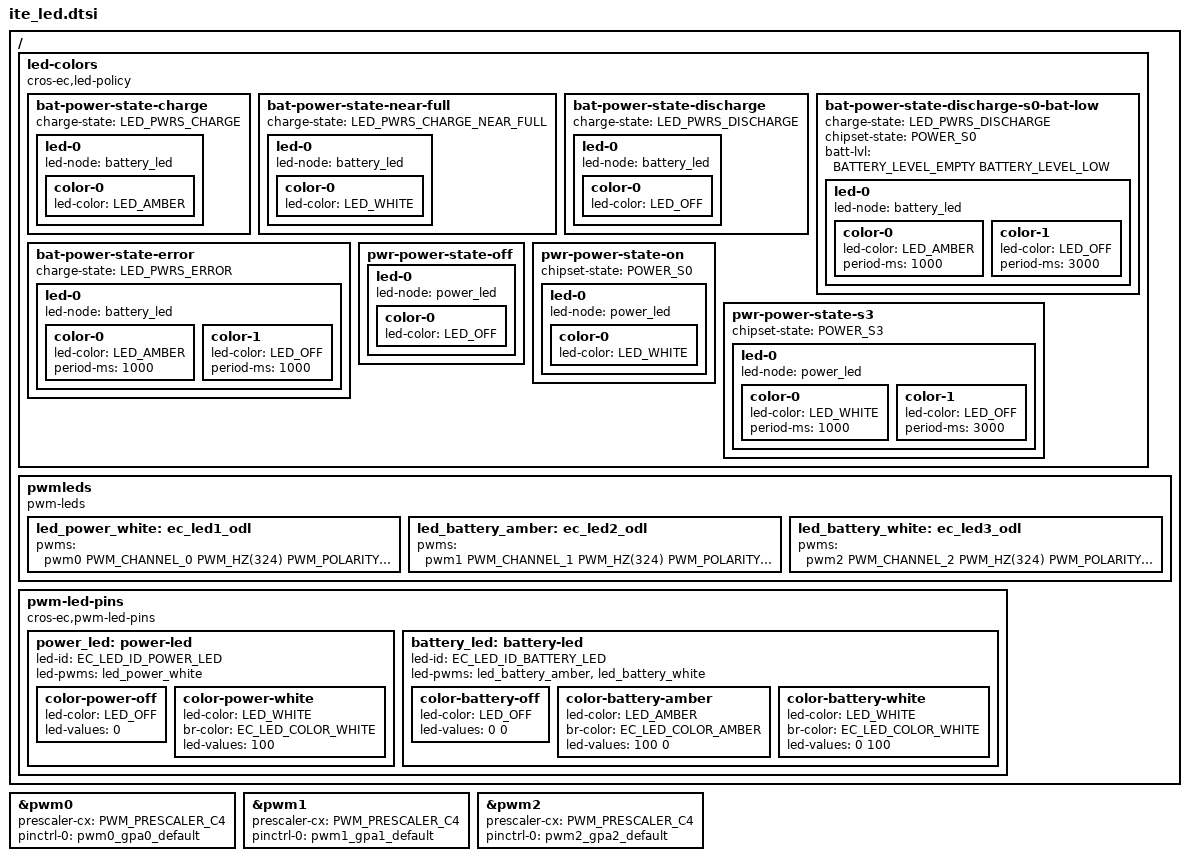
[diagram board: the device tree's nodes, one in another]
/* Copyright 2022 The ChromiumOS Authors
 * Use of this source code is governed by a BSD-style license that can be
 * found in the LICENSE file.
 */
#include <dt-bindings/battery.h>

/ {
	led-colors {
		compatible = "cros-ec,led-policy";

		bat-power-state-charge {
			charge-state = "LED_PWRS_CHARGE";

			led-0 {
				led-node = <&battery_led>;

				color-0 {
					led-color = "LED_AMBER";
				};
			};
		};

		bat-power-state-near-full {
			charge-state = "LED_PWRS_CHARGE_NEAR_FULL";

			led-0 {
				led-node = <&battery_led>;

				color-0 {
					led-color = "LED_WHITE";
				};
			};
		};

		bat-power-state-discharge {
			charge-state = "LED_PWRS_DISCHARGE";

			led-0 {
				led-node = <&battery_led>;

				color-0 {
					led-color = "LED_OFF";
				};
			};
		};

		bat-power-state-discharge-s0-bat-low {
			charge-state = "LED_PWRS_DISCHARGE";
			chipset-state = "POWER_S0";
			batt-lvl = <BATTERY_LEVEL_EMPTY BATTERY_LEVEL_LOW>;

			led-0 {
				led-node = <&battery_led>;

				color-0 {
					led-color = "LED_AMBER";
					period-ms = <1000>;
				};

				color-1 {
					led-color = "LED_OFF";
					period-ms = <3000>;
				};
			};
		};

		bat-power-state-error {
			charge-state = "LED_PWRS_ERROR";

			led-0 {
				led-node = <&battery_led>;

				color-0 {
					led-color = "LED_AMBER";
					period-ms = <1000>;
				};

				color-1 {
					led-color = "LED_OFF";
					period-ms = <1000>;
				};
			};
		};

		pwr-power-state-off {

			led-0 {
				led-node = <&power_led>;
				color-0 {
					led-color = "LED_OFF";
				};
			};
		};

		pwr-power-state-on {
			chipset-state = "POWER_S0";

			led-0 {
				led-node = <&power_led>;

				color-0 {
					led-color = "LED_WHITE";
				};
			};
		};

		pwr-power-state-s3 {
			chipset-state = "POWER_S3";

			led-0 {
				led-node = <&power_led>;

				color-0 {
					led-color = "LED_WHITE";
					period-ms = <1000>;
				};

				color-1 {
					led-color = "LED_OFF";
					period-ms = <3000>;
				};
			};
		};
	};

	pwmleds {
		compatible = "pwm-leds";

		/* NOTE: &pwm number needs same with channel number */
		led_power_white: ec_led1_odl {
			pwms = <&pwm0 PWM_CHANNEL_0 PWM_HZ(324) PWM_POLARITY_INVERTED>;
		};
		led_battery_amber: ec_led2_odl {
			pwms = <&pwm1 PWM_CHANNEL_1 PWM_HZ(324) PWM_POLARITY_INVERTED>;
		};
		led_battery_white: ec_led3_odl {
			pwms = <&pwm2 PWM_CHANNEL_2 PWM_HZ(324) PWM_POLARITY_INVERTED>;
		};
	};

	pwm-led-pins {
		compatible = "cros-ec,pwm-led-pins";

		power_led: power-led {
			led-id = "EC_LED_ID_POWER_LED";
			led-pwms = <&led_power_white>;

			color-power-off {
				led-color = "LED_OFF";
				led-values = <0>;
			};

			color-power-white {
				led-color = "LED_WHITE";
				br-color = "EC_LED_COLOR_WHITE";
				led-values = <100>;
			};
		};

		battery_led: battery-led {
			led-id = "EC_LED_ID_BATTERY_LED";
			led-pwms = <&led_battery_amber &led_battery_white>;

			color-battery-off {
				led-color = "LED_OFF";
				led-values = <0 0>;
			};

			color-battery-amber {
				led-color = "LED_AMBER";
				br-color = "EC_LED_COLOR_AMBER";
				led-values = <100 0>;
			};

			color-battery-white {
				led-color = "LED_WHITE";
				br-color = "EC_LED_COLOR_WHITE";
				led-values = <0 100>;
			};
		};
	};
};

/* LED1 */
&pwm0 {
	status = "okay";
	prescaler-cx = <PWM_PRESCALER_C4>;
	pinctrl-0 = <&pwm0_gpa0_default>;
	pinctrl-names = "default";
};

/* LED2 */
&pwm1 {
	status = "okay";
	prescaler-cx = <PWM_PRESCALER_C4>;
	pinctrl-0 = <&pwm1_gpa1_default>;
	pinctrl-names = "default";
};

/* LED3 */
&pwm2 {
	status = "okay";
	prescaler-cx = <PWM_PRESCALER_C4>;
	pinctrl-0 = <&pwm2_gpa2_default>;
	pinctrl-names = "default";
};
